# EG32M0x register map
Vendor: EGmicro Ltd.; Series: EG32M0x; File version: 1.0
CPU: CM0 r0p0, little endian, no MPU, no FPU, 3 interrupt priority bits
Registers are 32-bit, read-write, reset 0x0 unless marked. A register's access mark holds for its fields unless they carry their own. Offsets are from the block's base; [hi:lo] are bit positions.

## SPI — SPI unit
Base 0x400202C0
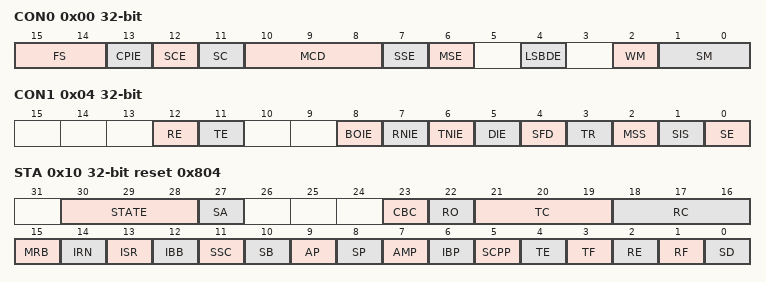
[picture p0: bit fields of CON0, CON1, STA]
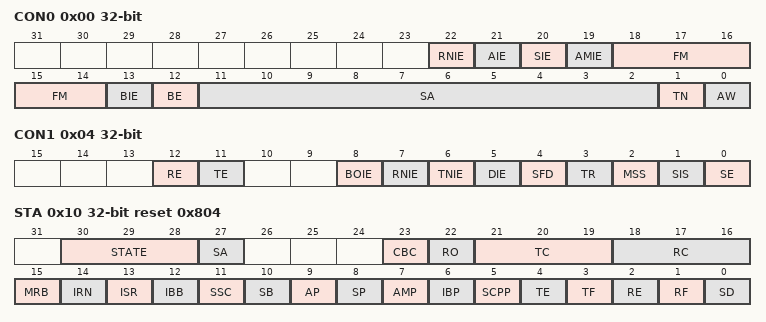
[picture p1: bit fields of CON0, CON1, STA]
0x00 CON0
  [15:14] FS — SPI data frame length
  [13] CPIE — Enable SPI rising edge interrupt from machine mode CS
  [12] SCE — SPI_CS pin enabled
  [11] SC — SPI CS pins control the output
  [10:8] MCD — SPI host mode delay sampling data
  [7] SSE — Enable SPI to synchronize input data in slave mode
  [6] MSE — Enable SPI to synchronize input data in master mode
  [4] LSBDE — The SPI transmits the lower-level function first
  [2] WM — SPI communication mode
  [1:0] SM — SPI interface clock polarity and sampling phase
0x04 CON1
  [12] RE — Receive DMA enablement control
  [11] TE — Send DMA enable control
  [8] BOIE — Enable receive buffer overflow interrupt
  [7] RNIE — The receive buffer is not broken in the air
  [6] TNIE — The send buffer unsatisfactory interrupt function was enabled
  [5] DIE — Enable data interruption after sending/receiving a frame
  [4] SFD — Select the full duplex mode
  [3] TR — Interface send/receive enable
  [2] MSS — The interface master/slave mode is set
  [1] SIS — SPI/IIC mode selection
  [0] SE — The SPI and IIC modules were enabled
0x08 CMD_DATA
  [31:0] CD — Read and write data registers
0x0C BAUD
  [15:0] BAUD — SSP baud rate
0x10 STA reset 0x804
  [30:28] STATE — IIC states
  [27] SA — IIC slave mode is addressed flag
  [23] CBC — The software writes 1 to the bit to clear TBUF_CNT and RBUF_CNT to zero
  [22] RO — Receive buffer overflow
  [21:19] TC — Indicates how many bytes of valid data are in the send buffer
  [18:16] RC — Indicates how many bytes of valid data are in the receive buffer
  [15] MRB — Indicates whether to read what needs to be read data length
  [14] IRN — The reply signal received at 9bit
  [13] ISR — The read and write flag received
  [12] IBB — The IIC detects that the line is busy
  [11] SSC — CS level state received by SPI from machine mode
  [10] SB — The status of the SPI/IIC when it is in host or slave mode
  [9] AP — Quorum loss is detected in the IIC host mode
  [8] SP — The IIC detects that the STOP bit is generated on the line
  [7] AMP — Received the correct slave address from the host
  [6] IBP — Broadcast address flag bit detected
  [5] SCPP — SPI detects CS pin rising edge from machine mode
  [4] TE — Send buffer empty flag
  [3] TF — Send buffer full flag
  [2] RE — Receive buffer empty flag
  [1] RF — Receive buffer full flag
  [0] SD — Data transmission completion mark
0x14 RONLY_CNT
  [11:0] RC — Length of data received by the SPI in half-duplex read-only mode

## IIC — IIC unit
Base 0x400202E0
0x00 CON0
  [22] RNIE — The NACK interrupt was received
  [21] AIE — The host quorum loss interrupt function was enabled
  [20] SIE — The STOP signal was detected online. The STOP signal was enabled
  [19] AMIE — The slave address matching interrupt was enabled
  [18:14] FM — IIC Each IIC_FILTER_CNT Indicates the clock of an IIC module
  [13] BIE — The IIC is disabled from receiving a broadcast address
  [12] BE — Enable the IIC to receive the broadcast address from the host
  [11:2] SA — IIC slave address
  [1] TN — Whether the IIC responds to the NACK when receiving data or the ACK select bit
  [0] AW — IIC slave IP address width
0x04 CON1
  [12] RE — Receive DMA enablement control
  [11] TE — Send DMA enable control
  [8] BOIE — Enable receive buffer overflow interrupt
  [7] RNIE — The receive buffer is not broken in the air
  [6] TNIE — The send buffer unsatisfactory interrupt function was enabled
  [5] DIE — Enable data interruption after sending/receiving a frame
  [4] SFD — Select the full duplex mode
  [3] TR — Interface send/receive enable
  [2] MSS — The interface master/slave mode is set
  [1] SIS — SPI/IIC mode selection
  [0] SE — The SPI and IIC modules were enabled
0x08 CMD_DATA
  [31:0] CD — Read and write data registers
0x0C BAUD
  [15:0] BAUD — SSP baud rate
0x10 STA reset 0x804
  [30:28] STATE — IIC states
  [27] SA — IIC slave mode is addressed flag
  [23] CBC — The software writes 1 to the bit to clear TBUF_CNT and RBUF_CNT to zero
  [22] RO — Receive buffer overflow
  [21:19] TC — Indicates how many bytes of valid data are in the send buffer
  [18:16] RC — Indicates how many bytes of valid data are in the receive buffer
  [15] MRB — Indicates whether to read what needs to be read data length
  [14] IRN — The reply signal received at 9bit
  [13] ISR — The read and write flag received
  [12] IBB — The IIC detects that the line is busy
  [11] SSC — CS level state received by SPI from machine mode
  [10] SB — The status of the SPI/IIC when it is in host or slave mode
  [9] AP — Quorum loss is detected in the IIC host mode
  [8] SP — The IIC detects that the STOP bit is generated on the line
  [7] AMP — Received the correct slave address from the host
  [6] IBP — Broadcast address flag bit detected
  [5] SCPP — SPI detects CS pin rising edge from machine mode
  [4] TE — Send buffer empty flag
  [3] TF — Send buffer full flag
  [2] RE — Receive buffer empty flag
  [1] RF — Receive buffer full flag
  [0] SD — Data transmission completion mark
0x14 RONLY_CNT
  [11:0] RC — Length of data received by the SPI in half-duplex read-only mode
